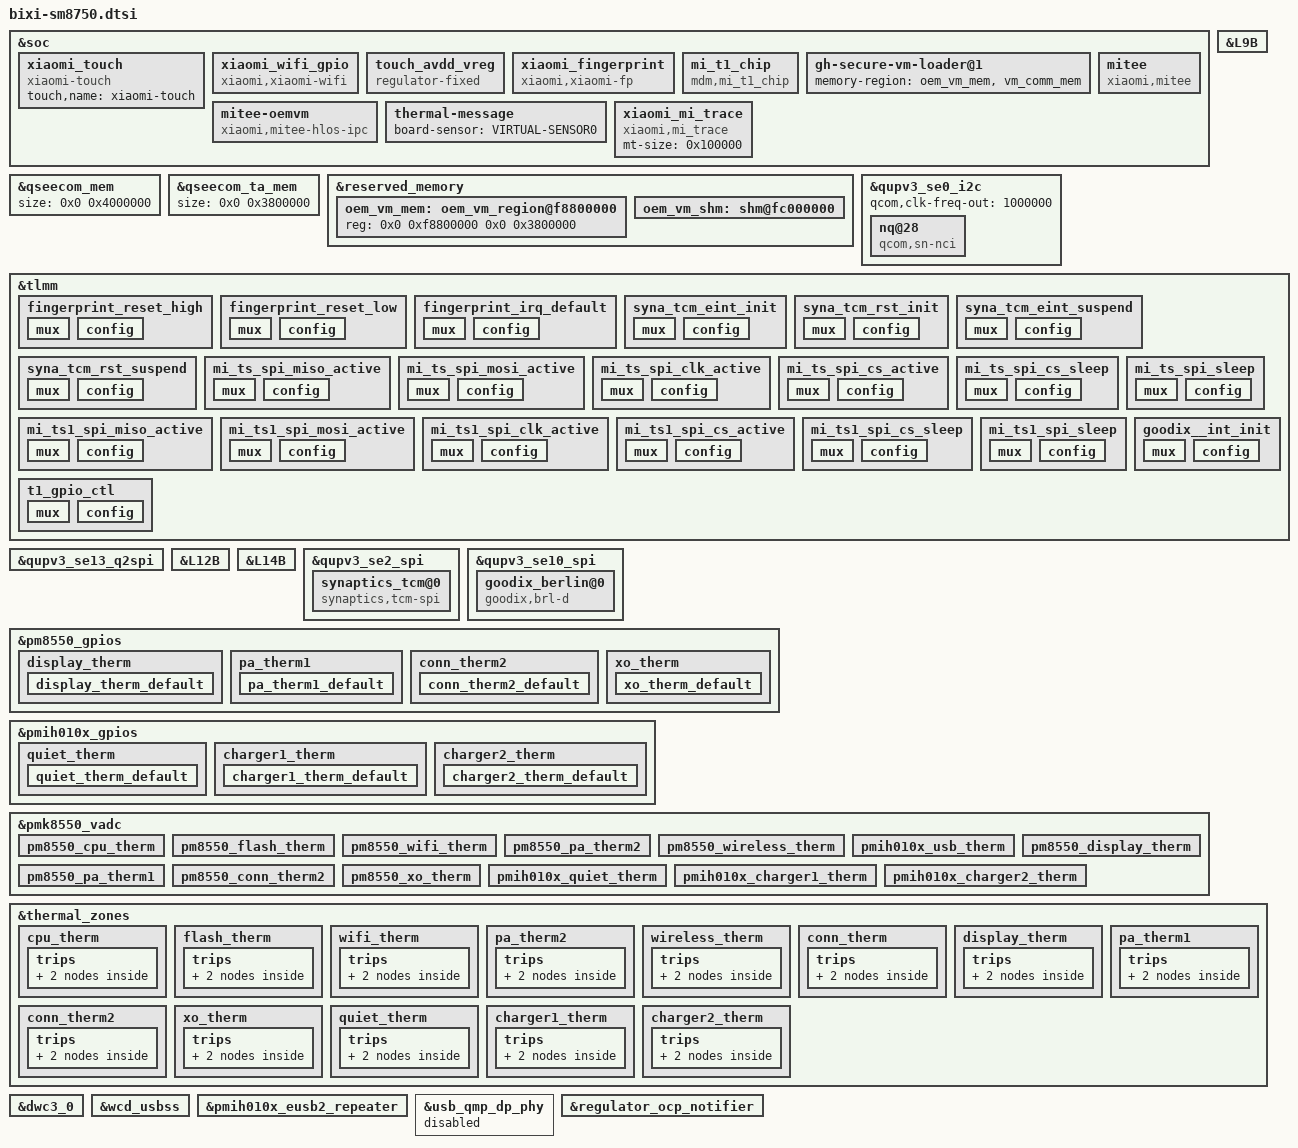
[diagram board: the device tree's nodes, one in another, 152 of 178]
/*
  this file is for attribution only of haotian
  And public attribution of xiaomi platforms(like O2 O3)
*/

#include "bixi-pinctrl.dtsi"
#include "sm8750-xiaomi-common.dtsi"
#include "sm8750-ir-sensor-common.dtsi"
#include "bixi-charger-common.dtsi"
#include <dt-bindings/interrupt-controller/arm-gic.h>

&soc {
	xiaomi_touch {
		compatible = "xiaomi-touch";
		status = "ok";
		touch,name = "xiaomi-touch";
	};

	xiaomi_wifi_gpio {
		compatible = "xiaomi,xiaomi-wifi";
		gpio = <&tlmm 79 0x00>;
		debounce-time = <30>;
		pinctrl-names = "default";
		pinctrl-0 = <&wifi_ctrl_irq>;
		status = "ok";
	};

	touch_avdd_vreg: touch_avdd_vreg {
		compatible = "regulator-fixed";
		regulator-name = "touch_avdd_vreg";
		enable-active-high;
		gpio = <&tlmm 112 0>;
	};

	xiaomi_fingerprint {
		compatible = "xiaomi,xiaomi-fp";
		xiaomi,gpio_irq = <&tlmm 85 0x0>;
		xiaomi,vendor_names = "O8_n1_141";
		fp_3v3_vreg-supply = <&L9B>;
		netlink-event = <25>;
		pinctrl-names = "reset_high", "reset_low","irq_default";
		pinctrl-0 = <&fingerprint_reset_high>;
		pinctrl-1 = <&fingerprint_reset_low>;
		pinctrl-2 = <&fingerprint_irq_default>;
		status = "ok";
	};
	
	mi_t1_chip {
		compatible = "mdm,mi_t1_chip";
		gpio-count = <4>;
		first-gpio = <125>;
		mi-t1-gpio-1 = <&tlmm 125 0x0>;
		mi-t1-gpio-2 = <&tlmm 126 0x0>;
		mi-t1-gpio-3 = <&tlmm 17 0x0>;
		mi-t1-gpio-4 = <&tlmm 58 0x0>;
		    pinctrl-0 = <&t1_gpio_ctl>;
	};
};

&qseecom_mem {
		size = <0x0 0x4000000>;
};

&qseecom_ta_mem {
		size = <0x0 0x3800000>;
};

/* mitee vm */
&reserved_memory {
	oem_vm_mem: oem_vm_region@f8800000 {
		reg = <0x0 0xf8800000 0x0 0x3800000>;
	};

	oem_vm_shm: shm@fc000000 {
		no-map;
		reg = <0x0 0xfc000000 0x0 0x400000>;
		gunyah-label = <0x3>;
	};
};

&soc {
	gh-secure-vm-loader@1 {
		memory-region = <&oem_vm_mem &vm_comm_mem>;
	};

	mitee: mitee {
		compatible = "xiaomi,mitee";
		binding-core = <4 5 6>;
		tui-supported;
	};

	mitee-oemvm {
		compatible = "xiaomi,mitee-hlos-ipc";
		xiaomi,master;
		gunyah-shm-label = <0x3>;
		peer-name = <0x4>;
		shared-buffer = <&oem_vm_shm>;
	};
};
/* mitee vm */

&qupv3_se0_i2c {
	status = "ok";
	qcom,clk-freq-out = <1000000>;
	#address-cells = <1>;
	#size-cells = <0>;
	nq@28 {
		compatible = "qcom,sn-nci";
		reg = <0x28>;
		qcom,sn-irq = <&tlmm 75 0x00>;
		qcom,sn-ven = <&tlmm 34 0x00>;
		qcom,sn-clkreq = <&tlmm 35 0x00>;
		qcom,sn-szone = "enable";
		interrupt-parent = <&tlmm>;
		interrupts = <75 0>;
		interrupt-names = "nfc_irq";
		pinctrl-names = "nfc_active", "nfc_suspend";
		pinctrl-0 = <&nfc_int_active &nfc_enable_active>;
		pinctrl-1 = <&nfc_int_suspend &nfc_enable_suspend>;
	};
};

&L9B {
	regulator-min-microvolt = <3300000>;
	regulator-max-microvolt = <3300000>;
	qcom,init-voltage = <3300000>;
};

&tlmm {
	/* FP_RESET_HIGH, state device active*/
	fingerprint_reset_high: fingerprint_reset_high {
		mux {
			pins = "gpio111";
			function = "gpi111";
		};
		config {
			pins = "gpio111";
			drive-strength = <2>;
			bias-disable;
			output-high;
		};
	};
	/* FP_RESET_LOW */
	fingerprint_reset_low: fingerprint_reset_low {
		mux {
			pins = "gpio111";
			function = "gpio";
		};
		config {
			pins = "gpio111";
			drive-strength = <2>;
			bias-disable;
			output-low;
		};
	};
	/* FP_INT_N */
		fingerprint_irq_default: fingerprint_irq_default {
		mux {
			pins = "gpio85";
			function = "gpio";
		};
		config {
			pins = "gpio85";
			drive-strength = <2>;
			bias-pull-down;
		};
	};
	syna_tcm_eint_init: syna_tcm_eint_init {
		mux {
			/* GPIO 162 Interrupt */
			pins = "gpio162";
			function = "gpio";
		};

		config {
			pins = "gpio162";
			bias-disable;
			input-enable;
		};
	};

	syna_tcm_rst_init: syna_tcm_rst_init {
		mux {
			/* GPIO 161 Interrupt */
			pins = "gpio161";
			function = "gpio";
		};

		config {
			pins = "gpio161";
			bias-disable;
			output-low;
		};
	};

	syna_tcm_eint_suspend: syna_tcm_eint_suspend {
		mux {
			/* GPIO 162 Interrupt */
			pins = "gpio162";
			function = "gpio";
		};

		config {
			pins = "gpio162";
			bias-pull-down;
		};
	};

	syna_tcm_rst_suspend: syna_tcm_rst_suspend {
		mux {
			/* GPIO 161 Interrupt */
			pins = "gpio161";
			function = "gpio";
		};

		config {
			pins = "gpio161";
			bias-pull-down;
			output-low;
		};
	};

	mi_ts_spi_miso_active: mi_ts_spi_miso_active {
		mux {
			pins = "gpio40";
			function = "qup1_se2_l0";
		};
		config {
			pins = "gpio40";
			drive-strength = <6>;
			bias-disable;
		};
	};

	mi_ts_spi_mosi_active: mi_ts_spi_mosi_active {
		mux {
			pins = "gpio41";
			function = "qup1_se2_l1";
		};
		config {
			pins = "gpio41";
			drive-strength = <6>;
			bias-disable;
		};
	};

	mi_ts_spi_clk_active: mi_ts_spi_clk_active {
		mux {
			pins = "gpio42";
			function = "qup1_se2_l2";
		};
		config {
			pins = "gpio42";
			drive-strength = <6>;
			bias-disable;
		};
	};

	mi_ts_spi_cs_active: mi_ts_spi_cs_active {
		mux {
			pins = "gpio43";
			function = "qup1_se2_l3";
		};
		config {
			pins = "gpio43";
			drive-strength = <6>;
			bias-disable;
		};
	};


	mi_ts_spi_cs_sleep: mi_ts_spi_cs_sleep {
		mux {
			pins = "gpio43";
			function = "gpio";
		};
		config {
			pins = "gpio43";
			drive-strength = <6>;
			bias-pull-down;
		};
	};

	mi_ts_spi_sleep: mi_ts_spi_sleep {
		mux {
			pins = "gpio40", "gpio41",
				"gpio42";
			function = "gpio";
		};
		config {
			pins = "gpio40", "gpio41",
				"gpio42";
			drive-strength = <2>;
			bias-pull-down;
		};
	};

	mi_ts1_spi_miso_active: mi_ts1_spi_miso_active {
		mux {
			pins = "gpio8";
			function = "qup2_se2_l0";
		};
		config {
			pins = "gpio8";
			drive-strength = <6>;
			bias-disable;
		};
	};

	mi_ts1_spi_mosi_active: mi_ts1_spi_mosi_active {
		mux {
			pins = "gpio9";
			function = "qup2_se2_l1";
		};
		config {
			pins = "gpio9";
			drive-strength = <6>;
			bias-disable;
		};
	};

	mi_ts1_spi_clk_active: mi_ts1_spi_clk_active {
		mux {
			pins = "gpio10";
			function = "qup2_se2_l2";
		};
		config {
			pins = "gpio10";
			drive-strength = <6>;
			bias-disable;
		};
	};

	mi_ts1_spi_cs_active: mi_ts1_spi_cs_active {
		mux {
			pins = "gpio11";
			function = "qup2_se2_l3";
		};
		config {
			pins = "gpio11";
			drive-strength = <6>;
			bias-disable;
		};
	};


	mi_ts1_spi_cs_sleep: mi_ts1_spi_cs_sleep {
		mux {
			pins = "gpio11";
			function = "gpio";
		};
		config {
			pins = "gpio11";
			drive-strength = <6>;
			bias-disable;
		};
	};


	mi_ts1_spi_sleep: mi_ts1_spi_sleep {
		mux {
			pins = "gpio8", "gpio9",
				"gpio10";
			function = "gpio";
		};
		config {
			pins = "gpio8", "gpio9",
				"gpio10";
			drive-strength = <2>;
			bias-disable;
		};
	};
	
	goodix__int_init: goodix__int_init {
		mux {
			/* GPIO 88 Interrupt */
			pins = "gpio88";
			function = "gpio";
		};

		config {
			pins = "gpio88";
			bias-disable;
			input-enable;
		};
	};

	t1_gpio_ctl: t1_gpio_ctl {
		mux {
			pins = "gpio125", "gpio126","gpio17", "gpio58";
			function = "gpio";
		};
		config {
			pins = "gpio125", "gpio126","gpio17", "gpio58";
			drive-strength = <2>;
			bias-disable;
			output-enable;
		};
	};

};

/* Ganges UWB Q2SPI SE Instance */
&qupv3_se13_q2spi {
	interrupts-extended = <&intc GIC_SPI 587 IRQ_TYPE_LEVEL_HIGH>,
				<&tlmm 23 IRQ_TYPE_LEVEL_HIGH>;
	mosi-pin = <&tlmm 21 0>;
	clk-pin = <&tlmm 22 0>;
	q2spi-max-frequency = <10000000>;
        status = "ok";
};

&L12B {
	regulator-min-microvolt = <1800000>;
	regulator-max-microvolt = <1800000>;
	qcom,init-voltage = <1800000>;
};

&L14B {
	regulator-min-microvolt = <3300000>;
	regulator-max-microvolt = <3300000>;
	qcom,init-voltage = <3300000>;
};

&qupv3_se2_spi {
	status = "ok";
	qcom,rt;
	pinctrl-0 = <&mi_ts_spi_mosi_active>, <&mi_ts_spi_miso_active>,
				<&mi_ts_spi_clk_active>;
	pinctrl-1 = <&mi_ts_spi_sleep>;
	synaptics_tcm@0 {
		compatible = "synaptics,tcm-spi";
		reg = <0x0>;
		spi-max-frequency = <15000000>;
		interrupt-parent = <&tlmm>;
		interrupts = <162 0x2008>;
		synaptics,avdd-name = "avdd";
		avdd-supply = <&touch_avdd_vreg>;
		synaptics,iovdd-name = "iovdd";
		iovdd-supply = <&L12B>;
		/*synaptics,bus-reg-name = "vdd";*/
		/*synaptics,pwr-reg-name = "avdd";*/
		synaptics,irq-gpio = <&tlmm 162 0x2008>;
		synaptics,reset-gpio = <&tlmm 161 0x00>;
		synaptics,irq-on-state = <0>;
		synaptics,spi-mode = <0>;
		synaptics,byte-delay-us = <0>;
		synaptics,block-delay-us = <0>;
		synaptics,power-delay-ms = <50>;
		synaptics,reset-active-ms = <10>;
		synaptics,reset-delay-ms = <200>;
		pinctrl-names = "pmx_ts_active","pmx_ts_suspend";
		pinctrl-0 = <&syna_tcm_eint_init &syna_tcm_rst_init &mi_ts_spi_cs_active>;
		pinctrl-1 = <&syna_tcm_eint_suspend &syna_tcm_rst_suspend &mi_ts_spi_cs_sleep>;
		synaptics,default-test-limit-name = "bixi_test_limits_S3910P.csv";
		qcom,smem-states = <&hallstate_smp2p_out 0>;
		mi_tp,game-mode-array =
				<1 0 0 0 0>;  /* MAX MIN DEF SET GET	*/
		mi_tp,active-mode-array =
				<1 0 0 0 0>;  /* MAX MIN DEF SET GET	*/
		mi_tp,tolerance-array =
				<4 0 2 2 2>;  /* MAX MIN DEF SET GET	*/
		mi_tp,up-threshold-array =
				<4 0 3 3 3>;  /* MAX MIN DEF SET GET	*/
		mi_tp,aim-sensitivity-array =
				<4 0 2 2 2>;  /* MAX MIN DEF SET GET	*/
		mi_tp,tap-stability-array =
				<4 0 2 2 2>;  /* MAX MIN DEF SET GET	*/
		mi_tp,edge-filter-array =
				<3 0 2 2 2>;  /* MAX MIN DEF SET GET	*/
		mi_tp,panel-orien-array =
				<3 0 0 0 0>;  /* MAX MIN DEF SET GET	*/
		mi_tp,report-rate-array =
				<3 0 0 0 0>;  /* MAX MIN DEF SET GET	*/
		mi_tp,expert-mode-array =
				<3 1 1 1 1>;  /* MAX MIN DEF SET GET	*/
		mi_tp,cornerfilter-area-step-array = <0 100 170 250>; /* step 0 to step 3 */
		mi_tp,cornerzone-filter-hor1-array =
                /* B0:Type, B1:pos, B2:x0, B3:y0, B4:x1, B5:y1, B6:reserved, B7: reserved */
                        <0 0 0 0 170 170 0 0>,
                        <0 1 0 0 0 0 0 0>,
                        <0 2 0 2741 170 2911 0 0>,
                        <0 3 0 0 0 0 0 0>;
		mi_tp,cornerzone-filter-hor2-array =
                /* B0:Type, B1:pos, B2:x0, B3:y0, B4:x1, B5:y1, B6:reserved, B7: reserved */
                        <0 0 0 0 0 0 0 0>,
                        <0 1 1053 0 1223 170 0 0>,
                        <0 2 0 0 0 0 0 0>,
                        <0 3 1053 2741 1223 2911 0 0>;
		mi_tp,cornerzone-filter-ver-array =
                /* B0:Type, B1:pos, B2:x0, B3:y0, B4:x1, B5:y1, B6:reserved, B7: reserved */
                        <0 0 0 0 0 0 0 0>,
                        <0 1 0 0 0 0 0 0>,
                        <0 2 0 2611 150 2911 0 0>,
                        <0 3 1073 2611 1223 2911 0 0>;
		mi_tp,deadzone-filter-hor-array =
                /* B0:Type, B1:pos, B2:x0, B3:y0, B4:x1, B5:y1, B6:reserved, B7: reserved */
                        <2 0 0 0 1223 5 0 0>,
                        <2 1 0 2906 1223 2911 0 0>,
                        <2 2 0 0 0 0 0 0>,
                        <2 3 0 0 0 0 0 0>;
		mi_tp,deadzone-filter-ver-array =
                /* B0:Type, B1:pos, B2:x0, B3:y0, B4:x1, B5:y1, B6:reserved, B7: reserved */
                        <2 0 0 0 0 0 0 0>,
                        <2 1 0 0 0 0 0 0>,
                        <2 2 0 0 5 2911 0 0>,
                        <2 3 1218 0 1223 2911 0 0>;
		mi_tp,edgezone-filter-hor-array =
                /* B0:Type, B1:pos, B2:x0, B3:y0, B4:x1, B5:y1, B6:reserved, B7: reserved */
                        <1 0 0 0 1223 40 0 0>,
                        <1 1 0 2871 1223 2911 0 0>,
                        <1 2 0 0 40 2911 0 0>,
                        <1 3 1183 0 1223 2911 0 0>;
		mi_tp,edgezone-filter-ver-array =
                /* B0:Type, B1:pos, B2:x0, B3:y0, B4:x1, B5:y1, B6:reserved, B7: reserved */
                        <1 0 0 0 0 0 0 0>,
                        <1 1 0 0 0 0 0 0>,
                        <1 2 0 0 40 2911 0 0>,
                        <1 3 1183 0 1223 2911 0 0>;
	};
};


&qupv3_se10_spi {
	status = "ok";
	qcom,rt;
	pinctrl-0 = <&mi_ts1_spi_mosi_active>, <&mi_ts1_spi_miso_active>,
				<&mi_ts1_spi_clk_active>;
	pinctrl-1 = <&mi_ts1_spi_sleep>;
	goodix_berlin@0 {
		compatible = "goodix,brl-d";
		reg = <0x0>;
		spi-max-frequency = <10000000>;
		//goodix,avdd-gpio = <&tlmm 106 0x00>;
		goodix,avdd-name = "avdd";
		avdd-supply = <&L14B>;
		goodix,iovdd-gpio = <&tlmm 89 0x00>;
		goodix,reset-gpio = <&tlmm 92 0x00>;
		goodix,irq-gpio = <&tlmm 88 0x00>;
		goodix,irq-flags = <2>;
		goodix,panel-max-x = <1208>;
		goodix,panel-max-y = <1392>;
		goodix,panel-max-w = <255>;

		goodix,panel-max-p = <4096>;
		goodix,sleep-enable;
		goodix,firmware-name = "goodix_firmware_bixi.bin";
		goodix,config-name = "goodix_cfg_group_bixi.bin";
		pinctrl-names = "pmx_ts1_active", "pmx_ts1_suspend";
		pinctrl-0 = <&mi_ts1_spi_cs_active &goodix__int_init>;
		pinctrl-1 = <&mi_ts1_spi_cs_sleep>;
		mi_tp,panel-orien-array =
				<3 0 0 0 0>;  /* MAX MIN DEF SET GET	*/
	};
};


&pm8550_gpios {
    display_therm {
            display_therm_default: display_therm_default {
            pins = "gpio2";
            bias-high-impedance;
            };
    };
};

&pm8550_gpios {
	pa_therm1 {
		pa_therm1_default: pa_therm1_default {
		pins = "gpio3";
		bias-high-impedance;
		};
	};
};

&pm8550_gpios {
	conn_therm2 {
		conn_therm2_default: conn_therm2_default {
		pins = "gpio4";
		bias-high-impedance;
		};
	};
};

&pm8550_gpios {
	xo_therm {
		xo_therm_default: xo_therm_default {
		pins = "gpio12";
		bias-high-impedance;
		};
	};
};

&pmih010x_gpios {
	quiet_therm {
		quiet_therm_default: quiet_therm_default {
		pins = "gpio6";
		bias-high-impedance;
		};
	};
};

&pmih010x_gpios {
	charger1_therm {
		charger1_therm_default: charger1_therm_default {
		pins = "gpio12";
		bias-high-impedance;
		};
	};
};

&pmih010x_gpios {
	charger2_therm {
		charger2_therm_default: charger2_therm_default {
		pins = "gpio18";
		bias-high-impedance;
		};
	};
};


&pmk8550_vadc {

	pinctrl-names = "default";
	pinctrl-0 =<&display_therm_default>,<&pa_therm1_default>,<&conn_therm2_default>,<&xo_therm_default>,<&quiet_therm_default>,<&charger1_therm_default>,<&charger2_therm_default>;

	pm8550_cpu_therm {
		reg = <PM8550_ADC5_GEN3_AMUX_THM1_100K_PU>;
		label = "pm8550_cpu_therm";
		qcom,ratiometric;
		qcom,hw-settle-time = <200>;
		qcom,pre-scaling = <1 1>;
		qcom,adc-tm-type = <1>;
	};

	pm8550_flash_therm {
		reg = <PM8550_ADC5_GEN3_AMUX_THM2_100K_PU>;
		label = "pm8550_flash_therm";
		qcom,ratiometric;
		qcom,hw-settle-time = <200>;
		qcom,pre-scaling = <1 1>;
		qcom,adc-tm-type = <1>;
	};

	pm8550_wifi_therm {
		reg = <PM8550_ADC5_GEN3_AMUX_THM3_100K_PU>;
		label = "pm8550_wifi_therm";
		qcom,ratiometric;
		qcom,hw-settle-time = <200>;
		qcom,pre-scaling = <1 1>;
		qcom,adc-tm-type = <1>;
	};

	pm8550_pa_therm2 {
		reg = <PM8550_ADC5_GEN3_AMUX_THM4_100K_PU>;
		label = "pm8550_pa_therm2";
		qcom,ratiometric;
		qcom,hw-settle-time = <200>;
		qcom,pre-scaling = <1 1>;
		qcom,adc-tm-type = <1>;
	};

	pm8550_wireless_therm {
		reg = <PM8550_ADC5_GEN3_AMUX_THM5_100K_PU>;
		label = "pm8550_wireless_therm";
		qcom,ratiometric;
		qcom,hw-settle-time = <200>;
		qcom,pre-scaling = <1 1>;
		qcom,adc-tm-type = <1>;
	};

	pmih010x_usb_therm {
		reg = <PMIH010X_ADC5_GEN4_AMUX_THM4_USB_THERM_100K_PU>;
		label = "pmih010x_usb_therm";
		qcom,ratiometric;
		qcom,hw-settle-time = <200>;
		qcom,pre-scaling = <1 1>;
		qcom,adc-tm-type = <1>;
		qcom,adc5-gen4;
	};

	pm8550_display_therm {
		reg = <PM8550_ADC5_GEN3_AMUX_THM6_GPIO2_100K_PU>;
		label = "pm8550_display_therm";
		qcom,ratiometric;
		qcom,pre-scaling = <1 1>;
		qcom,adc-tm-type = <1>;
	};

	pm8550_pa_therm1 {
		reg = <PM8550_ADC5_GEN3_AMUX1_GPIO3_100K_PU>;
		label = "pm8550_pa_therm1";
		qcom,ratiometric;
		qcom,pre-scaling = <1 1>;
		qcom,adc-tm-type = <1>;
	};

	pm8550_conn_therm2 {
		reg = <PM8550_ADC5_GEN3_AMUX2_GPIO4_100K_PU>;
		label = "pm8550_conn_therm2";
		qcom,ratiometric;
		qcom,pre-scaling = <1 1>;
		qcom,adc-tm-type = <1>;
	};

	pm8550_xo_therm {
		reg = <PM8550_ADC5_GEN3_AMUX4_GPIO12_100K_PU>;
		label = "pm8550_xo_therm";
		qcom,ratiometric;
		qcom,pre-scaling = <1 1>;
		qcom,adc-tm-type = <1>;
	};

	pmih010x_quiet_therm {
		reg = <PMIH010X_ADC5_GEN4_AMUX1_GPIO6_100K_PU>;
		label = "pmih010x_quiet_therm";
		qcom,ratiometric;
		qcom,pre-scaling = <1 1>;
		qcom,adc-tm-type = <1>;
        qcom,adc5-gen4;
	};

	pmih010x_charger1_therm {
		reg = <PMIH010X_ADC5_GEN4_AMUX4_GPIO12_100K_PU>;
		label = "pmih010x_charger1_therm";
		qcom,ratiometric;
		qcom,pre-scaling = <1 1>;
		qcom,adc-tm-type = <1>;
        qcom,adc5-gen4;
	};

	pmih010x_charger2_therm {
		reg = <PMIH010X_ADC5_GEN4_AMUX5_GPIO18_100K_PU>;
		label = "pmih010x_charger2_therm";
		qcom,ratiometric;
		qcom,pre-scaling = <1 1>;
		qcom,adc-tm-type = <1>;
        qcom,adc5-gen4;
	};

};

&thermal_zones {
	cpu_therm {
		polling-delay-passive = <0>;
		polling-delay = <0>;
		thermal-sensors = <&pmk8550_vadc PM8550_ADC5_GEN3_AMUX_THM1_100K_PU>;
		trips {
			active-config0 {
				temperature = <125000>;
				hysteresis = <1000>;
				type = "passive";
			};

			active-config1 {
				temperature = <125000>;
				hysteresis = <1000>;
				type = "passive";
			};
		};
	};

	flash_therm {
		polling-delay-passive = <0>;
		polling-delay = <0>;
		thermal-sensors = <&pmk8550_vadc PM8550_ADC5_GEN3_AMUX_THM2_100K_PU>;
		trips {
			active-config0 {
				temperature = <125000>;
				hysteresis = <1000>;
				type = "passive";
			};

			active-config1 {
				temperature = <125000>;
				hysteresis = <1000>;
				type = "passive";
			};
		};
	};

	wifi_therm {
		polling-delay-passive = <0>;
		polling-delay = <0>;
		thermal-sensors = <&pmk8550_vadc PM8550_ADC5_GEN3_AMUX_THM3_100K_PU>;
		trips {
			active-config0 {
				temperature = <125000>;
				hysteresis = <1000>;
				type = "passive";
			};

			active-config1 {
				temperature = <125000>;
				hysteresis = <1000>;
				type = "passive";
			};
		};
	};

	pa_therm2 {
		polling-delay-passive = <0>;
		polling-delay = <0>;
		thermal-sensors = <&pmk8550_vadc PM8550_ADC5_GEN3_AMUX_THM4_100K_PU>;
		trips {
			active-config0 {
				temperature = <125000>;
				hysteresis = <1000>;
				type = "passive";
			};

			active-config1 {
				temperature = <125000>;
				hysteresis = <1000>;
				type = "passive";
			};
		};
	};

	wireless_therm {
		polling-delay-passive = <0>;
		polling-delay = <0>;
		thermal-sensors = <&pmk8550_vadc PM8550_ADC5_GEN3_AMUX_THM5_100K_PU>;
		trips {
			active-config0 {
				temperature = <125000>;
				hysteresis = <1000>;
				type = "passive";
			};

			active-config1 {
				temperature = <125000>;
				hysteresis = <1000>;
				type = "passive";
			};
		};
	};

	conn_therm {
		polling-delay-passive = <0>;
		polling-delay = <0>;
		thermal-sensors = <&pmk8550_vadc PMIH010X_ADC5_GEN4_AMUX_THM4_USB_THERM_100K_PU>;
		trips {
			active-config0 {
				temperature = <125000>;
				hysteresis = <1000>;
				type = "passive";
			};

			active-config1 {
				temperature = <125000>;
				hysteresis = <1000>;
				type = "passive";
			};
		};
	};

	display_therm {
		polling-delay-passive = <0>;
		polling-delay = <0>;
		thermal-sensors = <&pmk8550_vadc PM8550_ADC5_GEN3_AMUX_THM6_GPIO2_100K_PU>;
		trips {
			active-config0 {
				temperature = <125000>;
				hysteresis = <1000>;
				type = "passive";
			};

			active-config1 {
				temperature = <125000>;
				hysteresis = <1000>;
				type = "passive";
			};
		};
	};

	pa_therm1 {
		polling-delay-passive = <0>;
		polling-delay = <0>;
		thermal-sensors = <&pmk8550_vadc PM8550_ADC5_GEN3_AMUX1_GPIO3_100K_PU>;
		trips {
			active-config0 {
				temperature = <125000>;
				hysteresis = <1000>;
				type = "passive";
			};

			active-config1 {
				temperature = <125000>;
				hysteresis = <1000>;
				type = "passive";
			};
		};
	};

	conn_therm2 {
		polling-delay-passive = <0>;
		polling-delay = <0>;
		thermal-sensors = <&pmk8550_vadc PM8550_ADC5_GEN3_AMUX2_GPIO4_100K_PU>;
		trips {
			active-config0 {
				temperature = <125000>;
				hysteresis = <1000>;
				type = "passive";
			};

			active-config1 {
				temperature = <125000>;
				hysteresis = <1000>;
				type = "passive";
			};
		};
	};

	xo_therm {
		polling-delay-passive = <0>;
		polling-delay = <0>;
		thermal-sensors = <&pmk8550_vadc PM8550_ADC5_GEN3_AMUX4_GPIO12_100K_PU>;
		trips {
			active-config0 {
				temperature = <125000>;
				hysteresis = <1000>;
				type = "passive";
			};

			active-config1 {
				temperature = <125000>;
				hysteresis = <1000>;
				type = "passive";
			};
		};
	};

	quiet_therm {
		polling-delay-passive = <0>;
		polling-delay = <0>;
		thermal-sensors = <&pmk8550_vadc PMIH010X_ADC5_GEN4_AMUX1_GPIO6_100K_PU>;
		trips {
			active-config0 {
				temperature = <125000>;
				hysteresis = <1000>;
				type = "passive";
			};

			active-config1 {
				temperature = <125000>;
				hysteresis = <1000>;
				type = "passive";
			};
		};
	};

	charger1_therm {
		polling-delay-passive = <0>;
		polling-delay = <0>;
		thermal-sensors = <&pmk8550_vadc PMIH010X_ADC5_GEN4_AMUX4_GPIO12_100K_PU>;
		trips {
			active-config0 {
				temperature = <125000>;
				hysteresis = <1000>;
				type = "passive";
			};

			active-config1 {
				temperature = <125000>;
				hysteresis = <1000>;
				type = "passive";
			};
		};
	};

	charger2_therm {
		polling-delay-passive = <0>;
		polling-delay = <0>;
		thermal-sensors = <&pmk8550_vadc PMIH010X_ADC5_GEN4_AMUX5_GPIO18_100K_PU>;
		trips {
			active-config0 {
				temperature = <125000>;
				hysteresis = <1000>;
				type = "passive";
			};

			active-config1 {
				temperature = <125000>;
				hysteresis = <1000>;
				type = "passive";
			};
		};
	};
};

&soc {
 	thermal-message {
  		board-sensor = "VIRTUAL-SENSOR0";
 	};
 };

&dwc3_0 {
	usb-phy = <&eusb2_phy0>, <&usb_nop_phy>;
	maximum-speed = "high-speed";
};

&wcd_usbss {
	wcd-equ-bw-settings = <0xF>;
	wcd-equ-bw-settings-host = <0x8>;
};

&pmih010x_eusb2_repeater {
	qcom,host-param-override-seq =
		<0x00 0x50
		0x0E 0x51
		0x01 0x52
		0x07 0x53
		0x03 0x54
		0x01 0x55
		0x03 0x56
		0x05 0x57
		0x02 0x58
		0x03 0x59
		0x03 0x5a
		0x02 0x5b>;
	qcom,param-override-seq =
		<0x00 0x50
		0x0E 0x51
		0x01 0x52
		0x07 0x53
		0x03 0x54
		0x03 0x55
		0x00 0x56
		0x06 0x57
		0x02 0x58
		0x03 0x59
		0x01 0x5a
		0x02 0x5b>;
	qcom,param-override-seq-host-ms =
		<0x00 0x50
		0x01 0x51
		0x01 0x52
		0x07 0x53
		0x03 0x54
		0x00 0x55
		0x03 0x56
		0x00 0x57
		0x02 0x58
		0x01 0x59
		0x03 0x5a
		0x02 0x5b>;
};
&usb_qmp_dp_phy {
	status = "disabled";
	usb3,eyegram-tuning;
	qcom,usb3-phy-eye-seq =
	/* <reg_offset, value>*/
		<USB3_DP_PCS_G12S1_TXMGN_V0 0x1F
			USB3_DP_PCS_G12S1_TXDEEMPH_M3P5DB 0x17>;
	qcom,host-usb3-phy-eye-seq =
		<USB3_DP_PCS_G12S1_TXMGN_V0 0x1F
			USB3_DP_PCS_G12S1_TXDEEMPH_M3P5DB 0x18>;
};

/*Remove PM8010 N for hardware design*/
&regulator_ocp_notifier {
	/delete-property/ periph-d40-supply;
	/delete-property/ periph-d41-supply;
	/delete-property/ periph-d42-supply;
	/delete-property/ periph-d43-supply;
	/delete-property/ periph-d44-supply;
	/delete-property/ periph-d45-supply;
	/delete-property/ periph-d46-supply;
};

&soc {
	xiaomi_mi_trace{
		compatible = "xiaomi,mi_trace";
		mt-size = <0x100000>;
	};
};
